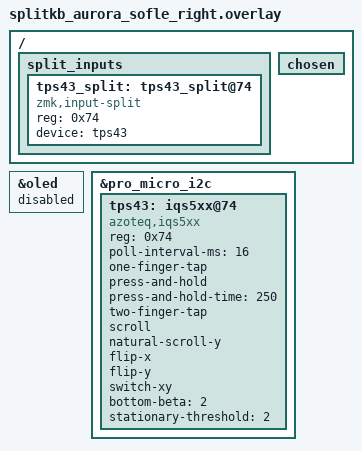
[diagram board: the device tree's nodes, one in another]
/ {
    /* Split input: forwards touchpad data from peripheral to central via BLE */
    split_inputs {
        #address-cells = <1>;
        #size-cells = <0>;

        tps43_split: tps43_split@74 {
            compatible = "zmk,input-split";
            reg = <0x74>;
            device = <&tps43>;
        };
    };

    /* Remove display chosen so ZMK display subsystem won't compile */
    chosen {
        /delete-property/ zephyr,display;
    };
};

/* Disable OLED — frees I2C bus for the touchpad */
&oled {
    status = "disabled";
};

&pro_micro_i2c {
    status = "okay";
    /* Stay at the 100kHz default: 400kHz was tried 2026-08-27 and caused
     * severe touchpad lag — the wiring/pull-ups are marginal at that speed
     * and corrupted reads silently. Do not raise this again. */

    tps43: iqs5xx@74 {
        compatible = "azoteq,iqs5xx";
        reg = <0x74>;

        /* No RDY pin — using polling mode (4 wires only: SDA, SCL, VCC, GND) */
        /* 16ms is the long-proven poll cadence for this board. The driver
         * syncs the chip's Active Report Rate to this value at setup, so
         * the clocks stay matched (no lost motion) at any interval. */
        poll-interval-ms = <16>;

        one-finger-tap;
        press-and-hold;
        press-and-hold-time = <250>;
        two-finger-tap;

        scroll;
        natural-scroll-y;

        /*
         * Axis mapping — TPS65 length (65mm) mounted vertically.
         *   flip-x;       ← invert horizontal
         *   flip-y;       ← invert vertical
         *   switch-xy;    ← swap X and Y axes
         */
        flip-x;
        flip-y;
        switch-xy;

        /* Tuning — 2 is the user's empirically preferred value; 5 was
         * tried 2026-08-27 and felt worse. */
        bottom-beta = <2>;
        stationary-threshold = <2>;
    };
};
